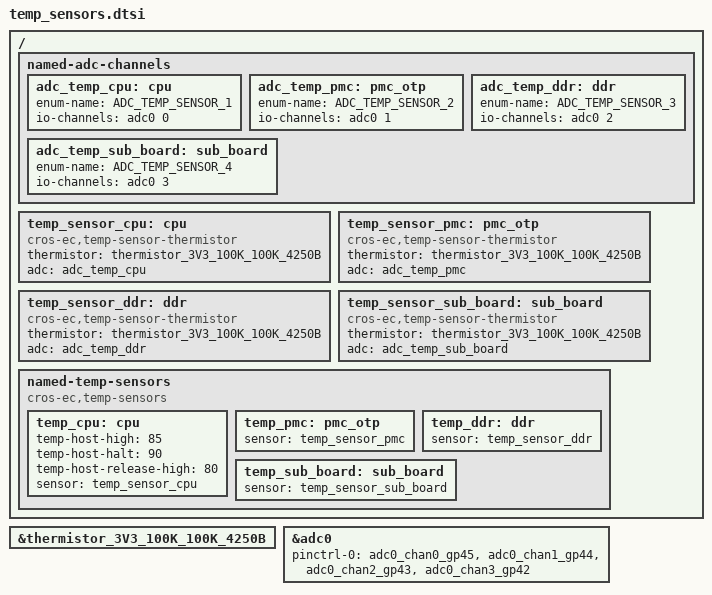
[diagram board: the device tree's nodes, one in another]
/* Copyright 2026 The ChromiumOS Authors
 * Use of this source code is governed by a BSD-style license that can be
 * found in the LICENSE file.
 */

#include <cros/thermistor/thermistor.dtsi>

/ {
	named-adc-channels {

		adc_temp_cpu: cpu {
			enum-name = "ADC_TEMP_SENSOR_1";
			io-channels = <&adc0 0>;
		};
		adc_temp_pmc: pmc_otp {
			enum-name = "ADC_TEMP_SENSOR_2";
			io-channels = <&adc0 1>;
		};
		adc_temp_ddr: ddr {
			enum-name = "ADC_TEMP_SENSOR_3";
			io-channels = <&adc0 2>;
		};
		adc_temp_sub_board: sub_board {
			enum-name = "ADC_TEMP_SENSOR_4";
			io-channels = <&adc0 3>;
		};
	};

	temp_sensor_cpu: cpu {
		compatible = "cros-ec,temp-sensor-thermistor";
		thermistor = <&thermistor_3V3_100K_100K_4250B>;
		adc = <&adc_temp_cpu>;
	};
	temp_sensor_pmc: pmc_otp {
		compatible = "cros-ec,temp-sensor-thermistor";
		thermistor = <&thermistor_3V3_100K_100K_4250B>;
		adc = <&adc_temp_pmc>;
	};
	temp_sensor_ddr: ddr {
		compatible = "cros-ec,temp-sensor-thermistor";
		thermistor = <&thermistor_3V3_100K_100K_4250B>;
		adc = <&adc_temp_ddr>;
	};
	temp_sensor_sub_board: sub_board {
		compatible = "cros-ec,temp-sensor-thermistor";
		thermistor = <&thermistor_3V3_100K_100K_4250B>;
		adc = <&adc_temp_sub_board>;
	};

	named-temp-sensors {
		compatible = "cros-ec,temp-sensors";
		temp_cpu: cpu {
			temp-host-high = <85>;
			temp-host-halt = <90>;
			temp-host-release-high = <80>;
			sensor = <&temp_sensor_cpu>;
		};
		temp_pmc: pmc_otp {
			sensor = <&temp_sensor_pmc>;
		};
		temp_ddr: ddr {
			sensor = <&temp_sensor_ddr>;
		};
		temp_sub_board: sub_board {
			sensor = <&temp_sensor_sub_board>;
		};
	};
};

&thermistor_3V3_100K_100K_4250B {
	status = "okay";
};

&adc0 {
	pinctrl-0 = <&adc0_chan0_gp45
		&adc0_chan1_gp44
		&adc0_chan2_gp43
		&adc0_chan3_gp42>;
	pinctrl-names = "default";
};
